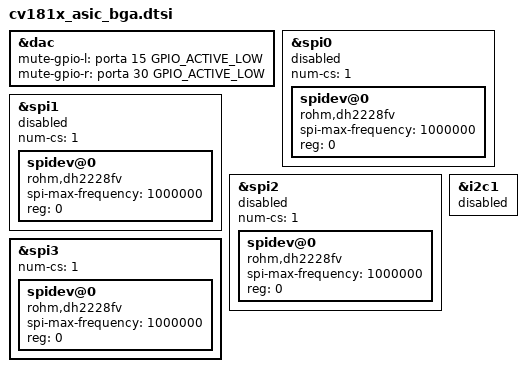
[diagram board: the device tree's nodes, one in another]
&dac{
	mute-gpio-l = <&porta 15 GPIO_ACTIVE_LOW>;
	mute-gpio-r = <&porta 30 GPIO_ACTIVE_LOW>;
};

&spi0 {
	status = "disabled";
	num-cs = <1>;
	spidev@0 {
		compatible = "rohm,dh2228fv";
		spi-max-frequency = <1000000>;
		reg = <0>;
	};
};

&spi1 {
	status = "disabled";
	num-cs = <1>;
	spidev@0 {
		compatible = "rohm,dh2228fv";
		spi-max-frequency = <1000000>;
		reg = <0>;
	};
};

&spi2 {
	status = "disabled";
	num-cs = <1>;
	spidev@0 {
		compatible = "rohm,dh2228fv";
		spi-max-frequency = <1000000>;
		reg = <0>;
	};
};

&spi3 {
	status = "okay";
	num-cs = <1>;
	spidev@0 {
		compatible = "rohm,dh2228fv";
		spi-max-frequency = <1000000>;
		reg = <0>;
	};
};

&i2c1 {
	status = "disabled";
};

/ {
	/delete-node/ i2s@04110000;
	/delete-node/ i2s@04120000;
	/delete-node/ sound_ext1;
	/delete-node/ sound_ext2;
	/delete-node/ sound_PDM;
};
